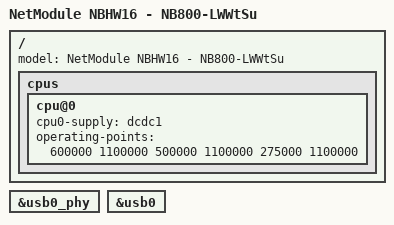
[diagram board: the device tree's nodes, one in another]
/*
 * Copyright (C) 2012 Texas Instruments Incorporated - http://www.ti.com/
 *
 * This program is free software; you can redistribute it and/or modify
 * it under the terms of the GNU General Public License version 2 as
 * published by the Free Software Foundation.
 */
#include "am335x-nbhw16-prod2.dts"

/ {
	model = "NetModule NBHW16 - NB800-LWWtSu";
	cpus {
		cpu@0 {
			cpu0-supply = <&dcdc1>;
			operating-points = <
				/* kHz	uV */
				600000  1100000
				500000  1100000
				275000  1100000
			>;
		};
	};
};

&usb0_phy {
	status = "okay";
};

&usb0 {
	status = "okay";
};

